AUTOSAR XML (schema 4-3-0)
package /HelloWorld_Generic/Services/Det
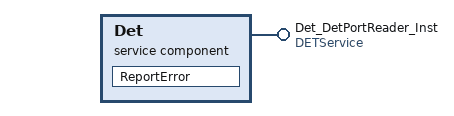
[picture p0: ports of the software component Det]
  service sw component type Det
    provide port Det_DetPortReader_Inst: provided-interface=DETService
    behavior DetBehavior: handle-termination-and-restart=NO-SUPPORT, port-api-option{port-arg-values=[{value=uint16:4097, value-type=uint16}, {value=uint8:0, value-type=uint8}], port=Det_DetPortReader_Inst}
      operation invoked event ReportError_Det_DetPortReader_Inst_ReportError: start-on-event=ReportError, operation=Det_DetPortReader_Inst.ReportError
      runnable ReportError: symbol=Det_ReportError
  swc implementation DetImpl: programming-language=C, vendor-id=60, behavior=DetBehavior
    code-descriptors:
      code src: artifact-descriptors=autosar-engineering-object={short-label=artifactDescriptor, category=artifactDescriptorCategory}
    resource consumption resourceConsumption
package /HelloWorld_Generic/Services/EcuM
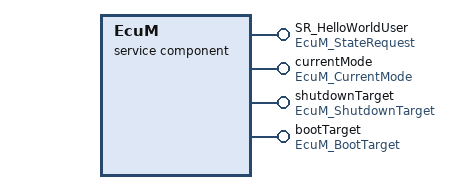
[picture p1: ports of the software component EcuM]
  service sw component type EcuM
    4 x provide port:
      SR_HelloWorldUser: provided-interface=EcuM_StateRequest
      currentMode: provided-interface=EcuM_CurrentMode
      shutdownTarget: provided-interface=EcuM_ShutdownTarget
      bootTarget: provided-interface=EcuM_BootTarget
    behavior EcuMFixedBehavior: data-type-mapping=EcuMFixedTypeMappings, handle-termination-and-restart=NO-SUPPORT, port-api-option{port-defined-argument-value{value=EcuM_UserType:0, value-type=EcuM_UserType}, port=SR_HelloWorldUser}
      9 x operation invoked event:
        RequestRUN_SR_HelloWorldUser_RequestRUN: start-on-event=RequestRUN, operation=SR_HelloWorldUser.RequestRUN
        ReleaseRUN_SR_HelloWorldUser_ReleaseRUN: start-on-event=ReleaseRUN, operation=SR_HelloWorldUser.ReleaseRUN
        RequestPOSTRUN_SR_HelloWorldUser_RequestPOSTRUN: start-on-event=RequestPOSTRUN, operation=SR_HelloWorldUser.RequestPOSTRUN
        ReleasePOSTRUN_SR_HelloWorldUser_ReleasePOSTRUN: start-on-event=ReleasePOSTRUN, operation=SR_HelloWorldUser.ReleasePOSTRUN
        SelectShutdownTarget_shutdownTarget_SelectShutdownTarget: start-on-event=SelectShutdownTarget, operation=shutdownTarget.SelectShutdownTarget
        GetShutdownTarget_shutdownTarget_GetShutdownTarget: start-on-event=GetShutdownTarget, operation=shutdownTarget.GetShutdownTarget
        GetLastShutdownTarget_shutdownTarget_GetLastShutdownTarget: start-on-event=GetLastShutdownTarget, operation=shutdownTarget.GetLastShutdownTarget
        SelectBootTarget_bootTarget_SelectBootTarget: start-on-event=SelectBootTarget, operation=bootTarget.SelectBootTarget
        GetBootTarget_bootTarget_GetBootTarget: start-on-event=GetBootTarget, operation=bootTarget.GetBootTarget
      10 x runnable:
        EcuM_MainFunction
          mode switch point modeSwitchPoint_EcuM_MainFunction_currentMode_currentMode: mode-group=currentMode.currentMode
        RequestRUN: can-be-invoked-concurrently=true, symbol=EcuM_RequestRUN
        ReleaseRUN: can-be-invoked-concurrently=true, symbol=EcuM_ReleaseRUN
        RequestPOSTRUN: can-be-invoked-concurrently=true, symbol=EcuM_RequestPOST_RUN
        ReleasePOSTRUN: can-be-invoked-concurrently=true, symbol=EcuM_ReleasePOST_RUN
        SelectShutdownTarget: can-be-invoked-concurrently=true, symbol=EcuM_SelectShutdownTarget
        GetShutdownTarget: can-be-invoked-concurrently=true, symbol=EcuM_GetShutdownTarget
        GetLastShutdownTarget: can-be-invoked-concurrently=true, symbol=EcuM_GetLastShutdownTarget
        SelectBootTarget: can-be-invoked-concurrently=true, symbol=EcuM_SelectBootTarget
        GetBootTarget: can-be-invoked-concurrently=true, symbol=EcuM_GetBootTarget
  swc implementation EcuMFixedImpl: programming-language=C, vendor-id=60, behavior=EcuMFixedBehavior
    code-descriptors:
      code src: artifact-descriptors=autosar-engineering-object={short-label=artifactDescriptor, category=artifactDescriptorCategory}
    resource consumption resourceConsumption
package /HelloWorld_Generic/Services/NvM
  4 x client server interface, all with is-service=true:
    NvMNotifyInitBlock
      operation InitBlock: possible-error=[NvMNotifyInitBlock/E_OK, NvMNotifyInitBlock/E_NOT_OK]
      error E_OK: error-code=0
      error E_NOT_OK: error-code=1
    NvMNotifyJobFinished
      operation JobFinished: possible-error=NvMNotifyJobFinished/E_OK
        arg ServiceId: type=uint8, direction=IN
        arg JobResult: type=NvM_RequestResultType, direction=IN
      error E_OK: error-code=0
    NvMService
      9 x operation, all with possible-error=[NvMService/E_OK, NvMService/E_NOT_OK]:
        GetErrorStatus
          arg RequestResultPtr: type=NvM_RequestResultType, direction=OUT
        SetDataIndex
          arg DataIndex: type=uint8, direction=IN
        GetDataIndex
          arg DataIndexPtr: type=uint8, direction=OUT
        SetRamBlockStatus
          arg BlockChanged: type=boolean, direction=IN
        ReadBlock
          arg DstPtr: type=VoidPtr, direction=IN
        WriteBlock
          arg SrcPtr: type=ConstVoidPtr, direction=IN
        RestoreBlockDefaults
          arg DstPtr: type=VoidPtr, direction=IN
        EraseNvBlock
        InvalidateNvBlock
      error E_OK: error-code=0
      error E_NOT_OK: error-code=1
    NvMAdmin
      operation SetBlockProtection: possible-error=[NvMAdmin/E_OK, NvMAdmin/E_NOT_OK]
        arg ProtectionEnabled: type=boolean, direction=IN
      error E_OK: error-code=0
      error E_NOT_OK: error-code=1
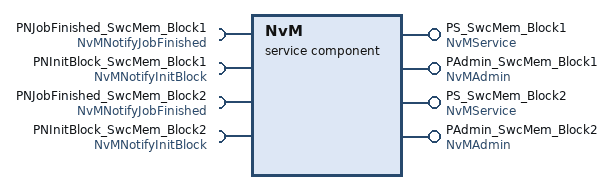
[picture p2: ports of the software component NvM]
  service sw component type NvM
    provide port PS_SwcMem_Block1: provided-interface=NvMService
    require port PNJobFinished_SwcMem_Block1: required-interface=NvMNotifyJobFinished
    require port PNInitBlock_SwcMem_Block1: required-interface=NvMNotifyInitBlock
    provide port PAdmin_SwcMem_Block1: provided-interface=NvMAdmin
    provide port PS_SwcMem_Block2: provided-interface=NvMService
    require port PNJobFinished_SwcMem_Block2: required-interface=NvMNotifyJobFinished
    require port PNInitBlock_SwcMem_Block2: required-interface=NvMNotifyInitBlock
    provide port PAdmin_SwcMem_Block2: provided-interface=NvMAdmin
    behavior NvMBehavior: handle-termination-and-restart=NO-SUPPORT
      20 x operation invoked event:
        GetErrorStatus_PS_SwcMem_Block1_GetErrorStatus: start-on-event=GetErrorStatus, operation=PS_SwcMem_Block1.GetErrorStatus
        GetErrorStatus_PS_SwcMem_Block2_GetErrorStatus: start-on-event=GetErrorStatus, operation=PS_SwcMem_Block2.GetErrorStatus
        SetDataIndex_PS_SwcMem_Block1_SetDataIndex: start-on-event=SetDataIndex, operation=PS_SwcMem_Block1.SetDataIndex
        SetDataIndex_PS_SwcMem_Block2_SetDataIndex: start-on-event=SetDataIndex, operation=PS_SwcMem_Block2.SetDataIndex
        GetDataIndex_PS_SwcMem_Block1_GetDataIndex: start-on-event=GetDataIndex, operation=PS_SwcMem_Block1.GetDataIndex
        GetDataIndex_PS_SwcMem_Block2_GetDataIndex: start-on-event=GetDataIndex, operation=PS_SwcMem_Block2.GetDataIndex
        SetRamBlockStatus_PS_SwcMem_Block1_SetRamBlockStatus: start-on-event=SetRamBlockStatus, operation=PS_SwcMem_Block1.SetRamBlockStatus
        SetRamBlockStatus_PS_SwcMem_Block2_SetRamBlockStatus: start-on-event=SetRamBlockStatus, operation=PS_SwcMem_Block2.SetRamBlockStatus
        ReadBlock_PS_SwcMem_Block1_ReadBlock: start-on-event=ReadBlock, operation=PS_SwcMem_Block1.ReadBlock
        ReadBlock_PS_SwcMem_Block2_ReadBlock: start-on-event=ReadBlock, operation=PS_SwcMem_Block2.ReadBlock
        WriteBlock_PS_SwcMem_Block1_WriteBlock: start-on-event=WriteBlock, operation=PS_SwcMem_Block1.WriteBlock
        WriteBlock_PS_SwcMem_Block2_WriteBlock: start-on-event=WriteBlock, operation=PS_SwcMem_Block2.WriteBlock
        RestoreBlockDefaults_PS_SwcMem_Block1_RestoreBlockDefaults: start-on-event=RestoreBlockDefaults, operation=PS_SwcMem_Block1.RestoreBlockDefaults
        RestoreBlockDefaults_PS_SwcMem_Block2_RestoreBlockDefaults: start-on-event=RestoreBlockDefaults, operation=PS_SwcMem_Block2.RestoreBlockDefaults
        EraseNvBlock_PS_SwcMem_Block1_EraseNvBlock: start-on-event=EraseNvBlock, operation=PS_SwcMem_Block1.EraseNvBlock
        EraseNvBlock_PS_SwcMem_Block2_EraseNvBlock: start-on-event=EraseNvBlock, operation=PS_SwcMem_Block2.EraseNvBlock
        InvalidateNvBlock_PS_SwcMem_Block1_InvalidateNvBlock: start-on-event=InvalidateNvBlock, operation=PS_SwcMem_Block1.InvalidateNvBlock
        InvalidateNvBlock_PS_SwcMem_Block2_InvalidateNvBlock: start-on-event=InvalidateNvBlock, operation=PS_SwcMem_Block2.InvalidateNvBlock
        SetBlockProtection_PAdmin_SwcMem_Block1_SetBlockProtection: start-on-event=SetBlockProtection, operation=PAdmin_SwcMem_Block1.SetBlockProtection
        SetBlockProtection_PAdmin_SwcMem_Block2_SetBlockProtection: start-on-event=SetBlockProtection, operation=PAdmin_SwcMem_Block2.SetBlockProtection
      port-api-options:
        {port-defined-argument-value{value=NvM_BlockIdType:2, value-type=NvM_BlockIdType}, port=PS_SwcMem_Block1}
        {port-defined-argument-value{value=NvM_BlockIdType:2, value-type=NvM_BlockIdType}, port=PAdmin_SwcMem_Block1}
        {port-defined-argument-value{value=NvM_BlockIdType:3, value-type=NvM_BlockIdType}, port=PS_SwcMem_Block2}
        {port-defined-argument-value{value=NvM_BlockIdType:3, value-type=NvM_BlockIdType}, port=PAdmin_SwcMem_Block2}
      11 x runnable:
        NvM_MainFunction
          4 x sync call, all with timeout=0.0:
            PNInitBlock_SwcMem_Block1_InitBlock: operation=PNInitBlock_SwcMem_Block1.InitBlock
            PNJobFinished_SwcMem_Block1_JobFinished: operation=PNJobFinished_SwcMem_Block1.JobFinished
            PNInitBlock_SwcMem_Block2_InitBlock: operation=PNInitBlock_SwcMem_Block2.InitBlock
            PNJobFinished_SwcMem_Block2_JobFinished: operation=PNJobFinished_SwcMem_Block2.JobFinished
        GetErrorStatus: can-be-invoked-concurrently=true, symbol=NvM_GetErrorStatus
        SetDataIndex: can-be-invoked-concurrently=true, symbol=NvM_SetDataIndex
        GetDataIndex: can-be-invoked-concurrently=true, symbol=NvM_GetDataIndex
        SetRamBlockStatus: can-be-invoked-concurrently=true, symbol=NvM_SetRamBlockStatus
        ReadBlock: can-be-invoked-concurrently=true, symbol=NvM_ReadBlock
        WriteBlock: can-be-invoked-concurrently=true, symbol=NvM_WriteBlock
        RestoreBlockDefaults: can-be-invoked-concurrently=true, symbol=NvM_RestoreBlockDefaults
        EraseNvBlock: can-be-invoked-concurrently=true, symbol=NvM_EraseNvBlock
        InvalidateNvBlock: can-be-invoked-concurrently=true, symbol=NvM_InvalidateNvBlock
        SetBlockProtection: can-be-invoked-concurrently=true, symbol=NvM_SetBlockProtection
  swc implementation NvMImpl: programming-language=C, vendor-id=60, behavior=NvMBehavior
    code-descriptors:
      code src: artifact-descriptors=autosar-engineering-object={short-label=artifactDescriptor, category=artifactDescriptorCategory}
    resource consumption resourceConsumption
package /HelloWorld_Generic/Services/Dlt
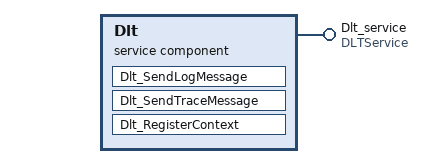
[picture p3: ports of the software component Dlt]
  service sw component type Dlt
    provide port Dlt_service: provided-interface=DLTService
    behavior DltBehavior: handle-termination-and-restart=NO-SUPPORT, port-api-option{port-defined-argument-value{value=Dlt_SessionIDType:4096, value-type=Dlt_SessionIDType}, port=Dlt_service}
      operation invoked event Dlt_SendLogMessage_Dlt_service_SendLogMessage: start-on-event=Dlt_SendLogMessage, operation=Dlt_service.SendLogMessage
      operation invoked event Dlt_SendTraceMessage_Dlt_service_SendTraceMessage: start-on-event=Dlt_SendTraceMessage, operation=Dlt_service.SendTraceMessage
      operation invoked event Dlt_RegisterContext_Dlt_service_RegisterContext: start-on-event=Dlt_RegisterContext, operation=Dlt_service.RegisterContext
      runnable Dlt_SendLogMessage
      runnable Dlt_SendTraceMessage
      runnable Dlt_RegisterContext
  swc implementation DltImpl: programming-language=C, vendor-id=60, behavior=DltBehavior
    code-descriptors:
      code src: artifact-descriptors=autosar-engineering-object={short-label=artifactDescriptor, category=artifactDescriptorCategory}
    resource consumption resourceConsumption
package /HelloWorld_Generic/Services/WdgM
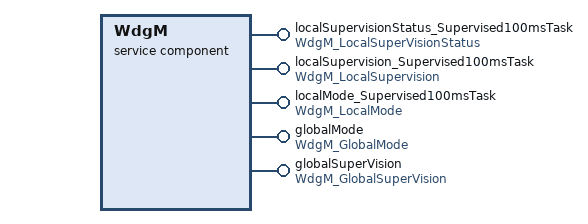
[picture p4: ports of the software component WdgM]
  service sw component type WdgM
    5 x provide port:
      localSupervisionStatus_Supervised100msTask: provided-interface=WdgM_LocalSuperVisionStatus
      localSupervision_Supervised100msTask: provided-interface=WdgM_LocalSupervision
      localMode_Supervised100msTask: provided-interface=WdgM_LocalMode
      globalMode: provided-interface=WdgM_GlobalMode
      globalSuperVision: provided-interface=WdgM_GlobalSuperVision
    behavior WdgMBehavior: data-type-mapping=WdgMTypeMappings, handle-termination-and-restart=NO-SUPPORT
      7 x operation invoked event:
        CheckpointReached_localSupervision_Supervised100msTask_CheckpointReached: start-on-event=CheckpointReached, operation=localSupervision_Supervised100msTask.CheckpointReached
        GetLocalStatus_localSupervisionStatus_Supervised100msTask_GetLocalStatus: start-on-event=GetLocalStatus, operation=localSupervisionStatus_Supervised100msTask.GetLocalStatus
        GetFirstExpiredSEID_globalSuperVision_GetFirstExpiredSEID: start-on-event=GetFirstExpiredSEID, operation=globalSuperVision.GetFirstExpiredSEID
        GetGlobalStatus_globalSuperVision_GetGlobalStatus: start-on-event=GetGlobalStatus, operation=globalSuperVision.GetGlobalStatus
        GetMode_globalSuperVision_GetMode: start-on-event=GetMode, operation=globalSuperVision.GetMode
        PerformReset_globalSuperVision_PerformReset: start-on-event=PerformReset, operation=globalSuperVision.PerformReset
        SetMode_globalSuperVision_SetMode: start-on-event=SetMode, operation=globalSuperVision.SetMode
      port-api-options:
        {port-defined-argument-value{value=WdgM_SupervisedEntityIdType:0, value-type=WdgM_SupervisedEntityIdType}, port=localSupervision_Supervised100msTask}
        {port-defined-argument-value{value=WdgM_SupervisedEntityIdType:0, value-type=WdgM_SupervisedEntityIdType}, port=localSupervisionStatus_Supervised100msTask}
        {indirect-api=true, port-defined-argument-value{value=WdgM_SupervisedEntityIdType:0, value-type=WdgM_SupervisedEntityIdType}, port=localMode_Supervised100msTask}
      8 x runnable:
        WdgM_MainFunction
          mode switch point modeSwitchPoint_WdgM_MainFunction_localMode_Supervised100msTask_currentMode: mode-group=localMode_Supervised100msTask.currentMode
          mode switch point modeSwitchPoint_WdgM_MainFunction_globalMode_currentMode: mode-group=globalMode.currentMode
        CheckpointReached: can-be-invoked-concurrently=true, symbol=WdgM_CheckpointReached
        GetLocalStatus: can-be-invoked-concurrently=true, symbol=WdgM_GetLocalStatus
        GetFirstExpiredSEID: can-be-invoked-concurrently=true, symbol=WdgM_GetFirstExpiredSEID
        GetGlobalStatus: can-be-invoked-concurrently=true, symbol=WdgM_GetGlobalStatus
        GetMode: can-be-invoked-concurrently=true, symbol=WdgM_GetMode
        PerformReset: can-be-invoked-concurrently=true, symbol=WdgM_PerformReset
        SetMode: can-be-invoked-concurrently=true, symbol=WdgM_SetMode
  swc implementation WdgMImpl: programming-language=C, vendor-id=60, behavior=WdgMBehavior
    code-descriptors:
      code src: artifact-descriptors=autosar-engineering-object={short-label=artifactDescriptor, category=artifactDescriptorCategory}
    resource consumption resourceConsumption
package /HelloWorld_Generic/Services/BswM
  impl type ComMModeEnum: compu {0=COMM_NO_COMMUNICATION, 1=COMM_SILENT_COMMUNICATION, 2=COMM_FULL_COMMUNICATION}, implementation-data-type=uint8
  impl type WdgMModeEnum: compu {0=SUPERVISION_DEACTIVATED, 1=SUPERVISION_FAILED, 2=SUPERVISION_EXPIRED, 3=SUPERVISION_STOPPED, 4=SUPERVISION_OK}, implementation-data-type=uint8
  sender receiver interface ComMModeRequestInterface
    data requestedMode: type=ComMModeEnum
  sender receiver interface WdgMModeRequestInterface
    data requestedMode: type=WdgMModeEnum
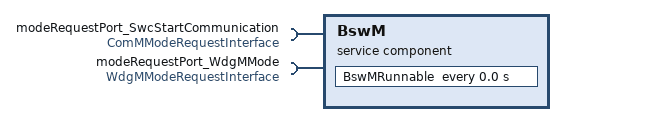
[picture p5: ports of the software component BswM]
  service sw component type BswM
    require port modeRequestPort_SwcStartCommunication: required-interface=ComMModeRequestInterface
    require port modeRequestPort_WdgMMode: required-interface=WdgMModeRequestInterface
    behavior BswMInternalBehavior: handle-termination-and-restart=NO-SUPPORT
      timing event BswMRunnableEvent: start-on-event=BswMRunnable, period=0.0
      runnable BswMRunnable: symbol=BswM_MainFunction
        data-receive-point-by-arguments:
          access dataReceivePoint_BswMRunnable_modeRequestPort_SwcStartCommunication_requestedMode: accessed-variable=modeRequestPort_SwcStartCommunication.requestedMode
          access dataReceivePoint_BswMRunnable_modeRequestPort_WdgMMode_requestedMode: accessed-variable=modeRequestPort_WdgMMode.requestedMode
  swc implementation BswMComponentImpl: programming-language=C, vendor-id=60, behavior=BswMInternalBehavior
    code-descriptors:
      code src: artifact-descriptors=autosar-engineering-object={short-label=artifactDescriptor, category=artifactDescriptorCategory}
    resource consumption resourceConsumption
package /HelloWorld_Generic/Services/Os
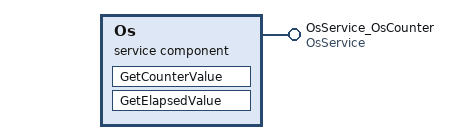
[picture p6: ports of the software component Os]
  service sw component type Os
    provide port OsService_OsCounter: provided-interface=OsService
    behavior OsBehavior: handle-termination-and-restart=NO-SUPPORT, port-api-option{port-defined-argument-value{value=CounterType:0, value-type=CounterType}, port=OsService_OsCounter}
      operation invoked event GetCounterValue_OsService_OsCounter_GetCounterValue: start-on-event=GetCounterValue, operation=OsService_OsCounter.GetCounterValue
      operation invoked event GetElapsedValue_OsService_OsCounter_GetElapsedValue: start-on-event=GetElapsedValue, operation=OsService_OsCounter.GetElapsedValue
      runnable GetCounterValue: symbol=Os_GetCounterValue
      runnable GetElapsedValue: symbol=Os_GetElapsedValue
  swc implementation OsImpl: programming-language=C, vendor-id=60, behavior=OsBehavior
    code-descriptors:
      code src: artifact-descriptors=autosar-engineering-object={short-label=artifactDescriptor, category=artifactDescriptorCategory}
    resource consumption resourceConsumption
package /HelloWorld_Generic/Services/FiM
  impl type FiM_FunctionIdType: implementation-data-type=uint16
  client server interface FunctionInhibition: is-service=true
    operation GetFunctionPermission: possible-error=[FunctionInhibition/E_OK, FunctionInhibition/E_NOT_OK]
      arg Permission: type=boolean, direction=OUT
    error E_OK: error-code=0
    error E_NOT_OK: error-code=1
  client server interface ControlFunctionAvailable: is-service=true
    operation SetFunctionAvailable: possible-error=[ControlFunctionAvailable/E_OK, ControlFunctionAvailable/E_NOT_OK]
      arg Availability: type=boolean, direction=IN
    error E_OK: error-code=0
    error E_NOT_OK: error-code=1
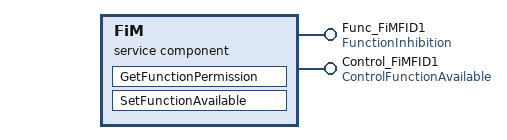
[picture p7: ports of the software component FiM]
  service sw component type FiM
    provide port Func_FiMFID1: provided-interface=FunctionInhibition
    provide port Control_FiMFID1: provided-interface=ControlFunctionAvailable
    behavior FiMBehavior: handle-termination-and-restart=NO-SUPPORT
      operation invoked event GetFunctionPermission_Func_FiMFID1_GetFunctionPermission: start-on-event=GetFunctionPermission, operation=Func_FiMFID1.GetFunctionPermission
      operation invoked event SetFunctionAvailable_Control_FiMFID1_SetFunctionAvailable: start-on-event=SetFunctionAvailable, operation=Control_FiMFID1.SetFunctionAvailable
      port-api-options:
        {port-defined-argument-value{value=FiM_FunctionIdType:0, value-type=FiM_FunctionIdType}, port=Func_FiMFID1}
        {port-defined-argument-value{value=FiM_FunctionIdType:0, value-type=FiM_FunctionIdType}, port=Control_FiMFID1}
      runnable GetFunctionPermission: can-be-invoked-concurrently=true, symbol=FiM_GetFunctionPermission
      runnable SetFunctionAvailable: can-be-invoked-concurrently=true, symbol=FiM_SetFunctionAvailable
  swc implementation FiMImpl: programming-language=C, vendor-id=60, behavior=FiMBehavior
    code-descriptors:
      code src: artifact-descriptors=autosar-engineering-object={short-label=artifactDescriptor, category=artifactDescriptorCategory}
    resource consumption resourceConsumption
package /HelloWorld_Generic/Services/ComM
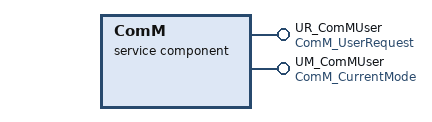
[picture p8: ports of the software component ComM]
  service sw component type ComM
    provide port UR_ComMUser: provided-interface=ComM_UserRequest
    provide port UM_ComMUser: provided-interface=ComM_CurrentMode
    behavior ComMBehavior: data-type-mapping=ComMTypeMappings, handle-termination-and-restart=NO-SUPPORT, port-api-option{port-defined-argument-value{value=ComM_UserHandleType:0, value-type=ComM_UserHandleType}, port=UR_ComMUser}
      4 x operation invoked event:
        RequestComMode_UR_ComMUser_RequestComMode: start-on-event=RequestComMode, operation=UR_ComMUser.RequestComMode
        GetMaxComMode_UR_ComMUser_GetMaxComMode: start-on-event=GetMaxComMode, operation=UR_ComMUser.GetMaxComMode
        GetRequestedComMode_UR_ComMUser_GetRequestedComMode: start-on-event=GetRequestedComMode, operation=UR_ComMUser.GetRequestedComMode
        GetCurrentComMode_UR_ComMUser_GetCurrentComMode: start-on-event=GetCurrentComMode, operation=UR_ComMUser.GetCurrentComMode
      5 x runnable:
        ComM_MainFunction
          mode switch point modeSwitchPoint_ComM_MainFunction_UM_ComMUser_currentMode: mode-group=UM_ComMUser.currentMode
        RequestComMode: can-be-invoked-concurrently=true, symbol=ComM_RequestComMode
        GetMaxComMode: can-be-invoked-concurrently=true, symbol=ComM_GetMaxComMode
        GetRequestedComMode: can-be-invoked-concurrently=true, symbol=ComM_GetRequestedComMode
        GetCurrentComMode: can-be-invoked-concurrently=true, symbol=ComM_GetCurrentComMode
  swc implementation ComMImpl: programming-language=C, vendor-id=60, behavior=ComMBehavior
    code-descriptors:
      code src: artifact-descriptors=autosar-engineering-object={short-label=artifactDescriptor, category=artifactDescriptorCategory}
    resource consumption resourceConsumption
package /HelloWorld_Generic/Services/IoHwAb
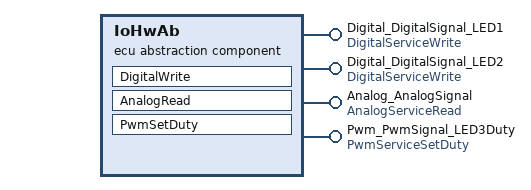
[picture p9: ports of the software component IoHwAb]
  ecu abstraction sw component type IoHwAb
    4 x provide port:
      Digital_DigitalSignal_LED1: provided-interface=DigitalServiceWrite
      Digital_DigitalSignal_LED2: provided-interface=DigitalServiceWrite
      Analog_AnalogSignal: provided-interface=AnalogServiceRead
      Pwm_PwmSignal_LED3Duty: provided-interface=PwmServiceSetDuty
    behavior IoHwAbBehavior: handle-termination-and-restart=NO-SUPPORT
      4 x operation invoked event:
        DigitalWrite_Digital_DigitalSignal_LED1_Write: start-on-event=DigitalWrite, operation=Digital_DigitalSignal_LED1.Write
        DigitalWrite_Digital_DigitalSignal_LED2_Write: start-on-event=DigitalWrite, operation=Digital_DigitalSignal_LED2.Write
        AnalogRead_Analog_AnalogSignal_Read: start-on-event=AnalogRead, operation=Analog_AnalogSignal.Read
        PwmSetDuty_Pwm_PwmSignal_LED3Duty_Set: start-on-event=PwmSetDuty, operation=Pwm_PwmSignal_LED3Duty.Set
      port-api-options:
        {port-defined-argument-value{value=IoHwAb_SignalType_:0, value-type=IoHwAb_SignalType_}, port=Digital_DigitalSignal_LED1}
        {port-defined-argument-value{value=IoHwAb_SignalType_:1, value-type=IoHwAb_SignalType_}, port=Digital_DigitalSignal_LED2}
        {port-defined-argument-value{value=IoHwAb_SignalType_:0, value-type=IoHwAb_SignalType_}, port=Analog_AnalogSignal}
        {port-defined-argument-value{value=IoHwAb_SignalType_:0, value-type=IoHwAb_SignalType_}, port=Pwm_PwmSignal_LED3Duty}
      runnable DigitalWrite: can-be-invoked-concurrently=true, symbol=IoHwAb_Digital_Write
      runnable AnalogRead: can-be-invoked-concurrently=true, symbol=IoHwAb_Analog_Read
      runnable PwmSetDuty: can-be-invoked-concurrently=true, symbol=IoHwAb_Pwm_Set_Duty
  swc implementation IoHwAbImpl: programming-language=C, vendor-id=60, behavior=IoHwAbBehavior
    code-descriptors:
      code src: artifact-descriptors=autosar-engineering-object={short-label=artifactDescriptor, category=artifactDescriptorCategory}
    resource consumption resourceConsumption
package /HelloWorld_Generic/Services/Dem
  impl type Dem_MaxDataValueType: category=ARRAY
    element Dem_MaxDataValueType_elementsImpl: array-size=33, array-size-semantics=FIXED-SIZE, implementation-data-type=uint8
  4 x client server interface, all with is-service=true:
    DiagnosticInfo
      7 x operation:
        GetEventStatus: possible-error=[DiagnosticInfo/E_OK, DiagnosticInfo/E_NOT_OK]
          arg EventStatusExtended: type=Dem_EventStatusExtendedType, direction=OUT
        GetEventFailed: possible-error=[DiagnosticInfo/E_OK, DiagnosticInfo/E_NOT_OK]
          arg EventFailed: type=boolean, direction=OUT
        GetEventTested: possible-error=[DiagnosticInfo/E_OK, DiagnosticInfo/E_NOT_OK]
          arg EventTested: type=boolean, direction=OUT
        GetDTCOfEvent: possible-error=[DiagnosticInfo/E_OK, DiagnosticInfo/E_NOT_OK, DiagnosticInfo/E_NO_DTC_AVAILABLE]
          arg DTCFormat: type=Dem_DTCFormatType, direction=IN
          arg DTCOfEvent: type=uint32, direction=OUT
        GetFaultDetectionCounter: possible-error=[DiagnosticInfo/E_OK, DiagnosticInfo/E_NOT_OK]
          arg FaultDetectionCounter: type=sint8, direction=OUT
        GetEventFreezeFrameData: possible-error=[DiagnosticInfo/E_OK, DiagnosticInfo/E_NOT_OK]
          4 x arg:
            RecordNumber: type=uint8, direction=IN
            ReportTotalRecord: type=boolean, direction=IN
            DataId: type=uint16, direction=IN
            DestBuffer: type=Dem_MaxDataValueType, direction=OUT
        GetEventExtendedDataRecord: possible-error=[DiagnosticInfo/E_OK, DiagnosticInfo/E_NOT_OK]
          arg RecordNumber: type=uint8, direction=IN
          arg DestBuffer: type=Dem_MaxDataValueType, direction=OUT
      error E_OK: error-code=0
      error E_NOT_OK: error-code=1
      error E_NO_DTC_AVAILABLE: error-code=2
    GeneralDiagnosticInfo
      7 x operation:
        GetEventStatus: possible-error=[GeneralDiagnosticInfo/E_OK, GeneralDiagnosticInfo/E_NOT_OK]
          arg EventId: type=Dem_EventIdType, direction=IN
          arg EventStatusExtended: type=Dem_EventStatusExtendedType, direction=OUT
        GetEventFailed: possible-error=[GeneralDiagnosticInfo/E_OK, GeneralDiagnosticInfo/E_NOT_OK]
          arg EventId: type=Dem_EventIdType, direction=IN
          arg EventFailed: type=boolean, direction=OUT
        GetEventTested: possible-error=[GeneralDiagnosticInfo/E_OK, GeneralDiagnosticInfo/E_NOT_OK]
          arg EventId: type=Dem_EventIdType, direction=IN
          arg EventTested: type=boolean, direction=OUT
        GetDTCOfEvent: possible-error=[GeneralDiagnosticInfo/E_OK, GeneralDiagnosticInfo/E_NOT_OK, GeneralDiagnosticInfo/E_NO_DTC_AVAILABLE]
          arg EventId: type=Dem_EventIdType, direction=IN
          arg DTCFormat: type=Dem_DTCFormatType, direction=IN
          arg DTCOfEvent: type=uint32, direction=OUT
        GetFaultDetectionCounter: possible-error=[GeneralDiagnosticInfo/E_OK, GeneralDiagnosticInfo/E_NOT_OK]
          arg EventId: type=Dem_EventIdType, direction=IN
          arg FaultDetectionCounter: type=sint8, direction=OUT
        GetEventFreezeFrameData: possible-error=[GeneralDiagnosticInfo/E_OK, GeneralDiagnosticInfo/E_NOT_OK]
          5 x arg:
            EventId: type=Dem_EventIdType, direction=IN
            RecordNumber: type=uint8, direction=IN
            ReportTotalRecord: type=boolean, direction=IN
            DataId: type=uint16, direction=IN
            DestBuffer: type=Dem_MaxDataValueType, direction=OUT
        GetEventExtendedDataRecord: possible-error=[GeneralDiagnosticInfo/E_OK, GeneralDiagnosticInfo/E_NOT_OK]
          arg EventId: type=Dem_EventIdType, direction=IN
          arg RecordNumber: type=uint8, direction=IN
          arg DestBuffer: type=Dem_MaxDataValueType, direction=OUT
      error E_OK: error-code=0
      error E_NOT_OK: error-code=1
      error E_NO_DTC_AVAILABLE: error-code=2
    OperationCycle
      operation SetOperationCycleState: possible-error=[OperationCycle/E_OK, OperationCycle/E_NOT_OK]
        arg CycleState: type=Dem_OperationCycleStateType, direction=IN
      error E_OK: error-code=0
      error E_NOT_OK: error-code=1
    EventAvailable
      operation SetEventAvailable: possible-error=[EventAvailable/E_OK, EventAvailable/E_NOT_OK]
        arg AvailableStatus: type=boolean, direction=IN
      error E_OK: error-code=0
      error E_NOT_OK: error-code=1
  service sw component type Dem
    5 x provide port:
      Event_TestEvent: provided-interface=DiagnosticMonitor
      EvtInfo_TestEvent: provided-interface=DiagnosticInfo
      GeneralEvtInfo: provided-interface=GeneralDiagnosticInfo
      OpCycle_DemOperationCycle: provided-interface=OperationCycle
      Dcm: provided-interface=DcmIf
    require port CBInitEvt_TestEvent: required-interface=CallbackInitMonitorForEvent
    provide port ControlEventAvailable_TestEvent: provided-interface=EventAvailable
    behavior DemBehavior: handle-termination-and-restart=NO-SUPPORT
      22 x operation invoked event:
        SetEventStatus_Event_TestEvent_SetEventStatus: start-on-event=SetEventStatus, operation=Event_TestEvent.SetEventStatus
        ResetEventStatus_Event_TestEvent_ResetEventStatus: start-on-event=ResetEventStatus, operation=Event_TestEvent.ResetEventStatus
        SetEventDisabled_Event_TestEvent_SetEventDisabled: start-on-event=SetEventDisabled, operation=Event_TestEvent.SetEventDisabled
        PrestoreFreezeFrame_Event_TestEvent_PrestoreFreezeFrame: start-on-event=PrestoreFreezeFrame, operation=Event_TestEvent.PrestoreFreezeFrame
        ClearPrestoredFreezeFrame_Event_TestEvent_ClearPrestoredFreezeFrame: start-on-event=ClearPrestoredFreezeFrame, operation=Event_TestEvent.ClearPrestoredFreezeFrame
        GetEventStatus_EvtInfo_TestEvent_GetEventStatus: start-on-event=GetEventStatus, operation=EvtInfo_TestEvent.GetEventStatus
        GetEventStatus_GeneralEvtInfo_GetEventStatus: start-on-event=GetEventStatus, operation=GeneralEvtInfo.GetEventStatus
        GetEventFailed_EvtInfo_TestEvent_GetEventFailed: start-on-event=GetEventFailed, operation=EvtInfo_TestEvent.GetEventFailed
        GetEventFailed_GeneralEvtInfo_GetEventFailed: start-on-event=GetEventFailed, operation=GeneralEvtInfo.GetEventFailed
        GetEventTested_EvtInfo_TestEvent_GetEventTested: start-on-event=GetEventTested, operation=EvtInfo_TestEvent.GetEventTested
        GetEventTested_GeneralEvtInfo_GetEventTested: start-on-event=GetEventTested, operation=GeneralEvtInfo.GetEventTested
        GetDTCOfEvent_EvtInfo_TestEvent_GetDTCOfEvent: start-on-event=GetDTCOfEvent, operation=EvtInfo_TestEvent.GetDTCOfEvent
        GetDTCOfEvent_GeneralEvtInfo_GetDTCOfEvent: start-on-event=GetDTCOfEvent, operation=GeneralEvtInfo.GetDTCOfEvent
        GetFaultDetectionCounter_EvtInfo_TestEvent_GetFaultDetectionCounter: start-on-event=GetFaultDetectionCounter, operation=EvtInfo_TestEvent.GetFaultDetectionCounter
        GetFaultDetectionCounter_GeneralEvtInfo_GetFaultDetectionCounter: start-on-event=GetFaultDetectionCounter, operation=GeneralEvtInfo.GetFaultDetectionCounter
        GetEventFreezeFrameData_EvtInfo_TestEvent_GetEventFreezeFrameData: start-on-event=GetEventFreezeFrameData, operation=EvtInfo_TestEvent.GetEventFreezeFrameData
        GetEventFreezeFrameData_GeneralEvtInfo_GetEventFreezeFrameData: start-on-event=GetEventFreezeFrameData, operation=GeneralEvtInfo.GetEventFreezeFrameData
        GetEventExtendedDataRecord_EvtInfo_TestEvent_GetEventExtendedDataRecord: start-on-event=GetEventExtendedDataRecord, operation=EvtInfo_TestEvent.GetEventExtendedDataRecord
        GetEventExtendedDataRecord_GeneralEvtInfo_GetEventExtendedDataRecord: start-on-event=GetEventExtendedDataRecord, operation=GeneralEvtInfo.GetEventExtendedDataRecord
        SetOperationCycleState_OpCycle_DemOperationCycle_SetOperationCycleState: start-on-event=SetOperationCycleState, operation=OpCycle_DemOperationCycle.SetOperationCycleState
        ClearDTC_Dcm_ClearDTC: start-on-event=ClearDTC, operation=Dcm.ClearDTC
        SetEventAvailable_ControlEventAvailable_TestEvent_SetEventAvailable: start-on-event=SetEventAvailable, operation=ControlEventAvailable_TestEvent.SetEventAvailable
      port-api-options:
        {port-defined-argument-value{value=Dem_EventIdType:6, value-type=Dem_EventIdType}, port=Event_TestEvent}
        {port-defined-argument-value{value=Dem_EventIdType:6, value-type=Dem_EventIdType}, port=EvtInfo_TestEvent}
        {port-defined-argument-value{value=Dem_EventIdType:6, value-type=Dem_EventIdType}, port=ControlEventAvailable_TestEvent}
        {port-defined-argument-value{value=Dem_OperationCycleIdType:2, value-type=Dem_OperationCycleIdType}, port=OpCycle_DemOperationCycle}
      16 x runnable:
        Dem_MainFunction
        SetEventStatus: can-be-invoked-concurrently=true, symbol=Dem_SetEventStatus
        ResetEventStatus: can-be-invoked-concurrently=true, symbol=Dem_ResetEventStatus
        SetEventDisabled: can-be-invoked-concurrently=true, symbol=Dem_SetEventDisabled
        PrestoreFreezeFrame: can-be-invoked-concurrently=true, symbol=Dem_PrestoreFreezeFrame
        ClearPrestoredFreezeFrame: can-be-invoked-concurrently=true, symbol=Dem_ClearPrestoredFreezeFrame
        GetEventStatus: can-be-invoked-concurrently=true, symbol=Dem_GetEventStatus
        GetEventFailed: can-be-invoked-concurrently=true, symbol=Dem_GetEventFailed
        GetEventTested: can-be-invoked-concurrently=true, symbol=Dem_GetEventTested
        GetDTCOfEvent: can-be-invoked-concurrently=true, symbol=Dem_GetDTCOfEvent
        GetFaultDetectionCounter: can-be-invoked-concurrently=true, symbol=Dem_GetFaultDetectionCounter
        GetEventFreezeFrameData: can-be-invoked-concurrently=true, symbol=Dem_GetEventFreezeFrameData
        GetEventExtendedDataRecord: can-be-invoked-concurrently=true, symbol=Dem_GetEventExtendedDataRecord
        SetOperationCycleState: can-be-invoked-concurrently=true, symbol=Dem_SetOperationCycleState
          sync call CBInitEvt_TestEvent_InitMonitorForEvent: operation=CBInitEvt_TestEvent.InitMonitorForEvent, timeout=0.0
        ClearDTC: symbol=Dem_ClearDTC
          sync call CBInitEvt_TestEvent_InitMonitorForEvent: operation=CBInitEvt_TestEvent.InitMonitorForEvent, timeout=0.0
        SetEventAvailable: can-be-invoked-concurrently=true, symbol=Dem_SetEventAvailable
  swc implementation DemImpl: programming-language=C, vendor-id=60, behavior=DemBehavior
    code-descriptors:
      code src: artifact-descriptors=autosar-engineering-object={short-label=artifactDescriptor, category=artifactDescriptorCategory}
    resource consumption resourceConsumption
package /HelloWorld_Generic/Services/Dcm
  impl type SRRead1_Data_DataType: compu {phys=raw}, implementation-data-type=uint16
  5 x impl type:
    SRRead2_Data_DataType: implementation-data-type=uint16
    SRRead3_Data_DataType: implementation-data-type=boolean
    SecurityLevel_0SeedType: category=ARRAY
      element SecurityLevel_0SeedType_elementsImpl: array-size=4, array-size-semantics=FIXED-SIZE, implementation-data-type=uint8
    SecurityLevel_0KeyType: category=ARRAY
      element SecurityLevel_0KeyType_elementsImpl: array-size=4, array-size-semantics=FIXED-SIZE, implementation-data-type=uint8
    DTRStatusType: implementation-data-type=uint8
  4 x mode switch interface, all with is-service=true:
    DcmEcuReset_Interface
      mode group DcmEcuReset: type=DcmEcuReset
    DcmRapidPowerShutDown_Interface
      mode group DcmRapidPowerShutDown: type=DcmModeRapidPowerShutDown
    DcmCommunicationControl_ComMChannel_Interface
      mode group DcmCommunicationControl_ComMChannel: type=DcmCommunicationControl
    DcmControlDTCSetting_Interface
      mode group DcmControlDTCSetting: type=DcmControlDTCSetting
  mode declaration group DcmDiagnosticSessionControl: initial-mode=DcmConf_DcmDspSessionRow_Default_Session
    mode DcmConf_DcmDspSessionRow_Default_Session
  mode switch interface DcmDiagnosticSessionControl_Interface: is-service=true
    mode group DcmDiagnosticSessionControl: type=DcmDiagnosticSessionControl
  data type mapping set ModeGroupTypeMappings
    mode-request-type-maps:
      implementation-data-type=uint8, mode-group=DcmEcuReset
      implementation-data-type=uint8, mode-group=DcmModeRapidPowerShutDown
      implementation-data-type=uint8, mode-group=DcmCommunicationControl
      implementation-data-type=uint8, mode-group=DcmControlDTCSetting
      implementation-data-type=uint8, mode-group=DcmDiagnosticSessionControl
  impl type SRWrite1_Data_DataType: implementation-data-type=uint16
  impl type SRWrite2_Data_DataType: compu {phys=raw}, implementation-data-type=uint16
  5 x sender receiver interface:
    DataServices_SRWrite1_Data
      data Data: type=SRWrite1_Data_DataType
    DataServices_SRWrite2_Data
      data Data: type=SRWrite2_Data_DataType
    DataServices_SRRead1_Data
      data Data: type=SRRead1_Data_DataType
    DataServices_SRRead2_Data
      data Data: type=SRRead2_Data_DataType
    DataServices_SRRead3_Data
      data Data: type=SRRead3_Data_DataType
  client server interface SecurityAccess_SecurityLevel_0: is-service=true
    operation GetSeed: possible-error=[SecurityAccess_SecurityLevel_0/E_OK, SecurityAccess_SecurityLevel_0/E_NOT_OK, E_PENDING]
      arg OpStatus: type=Dcm_OpStatusType, direction=IN
      arg Seed: type=SecurityLevel_0SeedType, direction=OUT
      arg ErrorCode: type=Dcm_NegativeResponseCodeType, direction=OUT
    operation CompareKey: possible-error=[SecurityAccess_SecurityLevel_0/E_OK, SecurityAccess_SecurityLevel_0/E_NOT_OK, E_PENDING, E_COMPARE_KEY_FAILED]
      arg Key: type=SecurityLevel_0KeyType, direction=IN
      arg OpStatus: type=Dcm_OpStatusType, direction=IN
    4 x error:
      E_OK: error-code=0
      E_NOT_OK: error-code=1
      E_PENDING: error-code=10
      E_COMPARE_KEY_FAILED: error-code=11
  client server interface DCMServices: is-service=true
    4 x operation:
      GetActiveProtocol: possible-error=DCMServices/E_OK
        arg ActiveProtocol: type=Dcm_ProtocolType, direction=OUT
      GetSecurityLevel: possible-error=[DCMServices/E_OK, DCMServices/E_NOT_OK]
        arg SecLevel: type=Dcm_SecLevelType, direction=OUT
      GetSesCtrlType: possible-error=[DCMServices/E_OK, DCMServices/E_NOT_OK]
        arg SesCtrlType: type=Dcm_SesCtrlType, direction=OUT
      ResetToDefaultSession: possible-error=[DCMServices/E_OK, DCMServices/E_NOT_OK]
    error E_OK: error-code=0
    error E_NOT_OK: error-code=1
  client server interface DTRServices: is-service=true
    operation GetDTRValue: possible-error=[DTRServices/E_OK, DTRServices/E_NOT_OK]
      5 x arg:
        OpStatus: type=Dcm_OpStatusType, direction=IN
        Testval: type=uint16, direction=OUT
        Minlimit: type=uint16, direction=OUT
        Maxlimit: type=uint16, direction=OUT
        Status: type=DTRStatusType, direction=OUT
    error E_OK: error-code=0
    error E_NOT_OK: error-code=1
  service sw component type Dcm
    provide port DataServices_SRWrite1_Data_Write: provided-interface=DataServices_SRWrite1_Data
    provide port DataServices_SRWrite2_Data_Write: provided-interface=DataServices_SRWrite2_Data
    5 x require port:
      DataServices_SRRead{1..3}_Data: required-interface=DataServices_SRRead{1..3}_Data
      SecurityAccess_SecurityLevel_0: required-interface=SecurityAccess_SecurityLevel_0
      CallbackDCMRequestServices_DcmDslCallbackDCMRequestService: required-interface=CallbackDCMRequestServices
    5 x provide port:
      DcmEcuReset: provided-interface=DcmEcuReset_Interface
      DcmRapidPowerShutDown: provided-interface=DcmRapidPowerShutDown_Interface
      DcmCommunicationControl_ComMChannel: provided-interface=DcmCommunicationControl_ComMChannel_Interface
      DcmControlDTCSetting: provided-interface=DcmControlDTCSetting_Interface
      DcmDiagnosticSessionControl: provided-interface=DcmDiagnosticSessionControl_Interface
    require port DcmIf: required-interface=DcmIf
    provide port DCMServices: provided-interface=DCMServices
    behavior DcmBehavior: data-type-mapping=ModeGroupTypeMappings, handle-termination-and-restart=NO-SUPPORT
      4 x operation invoked event:
        Dcm_GetSecurityLevel_DCMServices_GetSecurityLevel: start-on-event=Dcm_GetSecurityLevel, operation=DCMServices.GetSecurityLevel
        Dcm_GetSesCtrlType_DCMServices_GetSesCtrlType: start-on-event=Dcm_GetSesCtrlType, operation=DCMServices.GetSesCtrlType
        Dcm_GetActiveProtocol_DCMServices_GetActiveProtocol: start-on-event=Dcm_GetActiveProtocol, operation=DCMServices.GetActiveProtocol
        Dcm_ResetToDefaultSession_DCMServices_ResetToDefaultSession: start-on-event=Dcm_ResetToDefaultSession, operation=DCMServices.ResetToDefaultSession
      timing event Dcm_MainFunction_TimingEvent: start-on-event=Dcm_MainFunction, period=0.0
      5 x runnable:
        Dcm_GetSecurityLevel: can-be-invoked-concurrently=true
        Dcm_GetSesCtrlType: can-be-invoked-concurrently=true
        Dcm_GetActiveProtocol: can-be-invoked-concurrently=true
        Dcm_ResetToDefaultSession: can-be-invoked-concurrently=true
        Dcm_MainFunction
          data-receive-point-by-arguments:
            access dataReceivePoint_Dcm_MainFunction_DataServices_SRRead{1..3}_Data_Data: accessed-variable=DataServices_SRRead{1..3}_Data.Data
          data-send-points:
            access dataSendPoint_Dcm_MainFunction_DataServices_SRWrite1_Data_Write_Data: accessed-variable=DataServices_SRWrite1_Data_Write.Data
            access dataSendPoint_Dcm_MainFunction_DataServices_SRWrite2_Data_Write_Data: accessed-variable=DataServices_SRWrite2_Data_Write.Data
          5 x mode switch point:
            modeSwitchPoint_Dcm_MainFunction_DcmEcuReset_DcmEcuReset: mode-group=DcmEcuReset.DcmEcuReset
            modeSwitchPoint_Dcm_MainFunction_DcmRapidPowerShutDown_DcmRapidPowerShutDown: mode-group=DcmRapidPowerShutDown.DcmRapidPowerShutDown
            modeSwitchPoint_Dcm_MainFunction_DcmCommunicationControl_ComMChannel_DcmCommunicationControl_ComMChannel: mode-group=DcmCommunicationControl_ComMChannel.DcmCommunicationControl_ComMChannel
            modeSwitchPoint_Dcm_MainFunction_DcmControlDTCSetting_DcmControlDTCSetting: mode-group=DcmControlDTCSetting.DcmControlDTCSetting
            modeSwitchPoint_Dcm_MainFunction_DcmDiagnosticSessionControl_DcmDiagnosticSessionControl: mode-group=DcmDiagnosticSessionControl.DcmDiagnosticSessionControl
          5 x sync call, all with timeout=0.0:
            SecurityAccess_SecurityLevel_0_GetSeed: operation=SecurityAccess_SecurityLevel_0.GetSeed
            SecurityAccess_SecurityLevel_0_CompareKey: operation=SecurityAccess_SecurityLevel_0.CompareKey
            CallbackDCMRequestServices_DcmDslCallbackDCMRequestService_StartProtocol: operation=CallbackDCMRequestServices_DcmDslCallbackDCMRequestService.StartProtocol
            CallbackDCMRequestServices_DcmDslCallbackDCMRequestService_StopProtocol: operation=CallbackDCMRequestServices_DcmDslCallbackDCMRequestService.StopProtocol
            DcmIf_ClearDTC: operation=DcmIf.ClearDTC
  swc implementation DcmImpl: programming-language=C, vendor-id=60, behavior=DcmBehavior
    code-descriptors:
      code src: artifact-descriptors=autosar-engineering-object={short-label=artifactDescriptor, category=artifactDescriptorCategory}
    resource consumption resourceConsumption
package /HelloWorld
  composition sw component type TopLevelComposition
    provide port Tx01: provided-interface=BasicSRInterface
    provide port TxAdc: provided-interface=BasicSRInterface2
    require port Rx01: required-interface=BasicSRInterface
    require port Rx01: required-interface=BasicSRInterface
    provide port MemTx: provided-interface=MemoryResIf
    require port MemRx: required-interface=MemoryCmdIf
    15 x component:
      SwcReader: type=SwcReaderType
      SwcWriter: type=SwcWriterType
      SwcMem: type=SwcMemType
      ecuM: type=EcuM
      ioHwAb: type=IoHwAb
      comM: type=ComM
      dcm: type=Dcm
      det: type=Det
      dlt: type=Dlt
      dem: type=Dem
      bswm: type=BswM
      wdgm: type=WdgM
      nvm: type=NvM
      os: type=Os
      fim: type=FiM
    connect ioHwAb.Digital_DigitalSignal_LED1 -> SwcReader.Blinker
    connect SwcReader.ResultPort -> SwcWriter.InputPort
    connect ioHwAb.Digital_DigitalSignal_LED2 -> SwcWriter.Blinker
    connect ioHwAb.Analog_AnalogSignal -> SwcReader.AnalogReader
    connect ioHwAb.Pwm_PwmSignal_LED3Duty -> SwcReader.PWMWriter
    connect ecuM.SR_HelloWorldUser -> SwcReader.RunControl
    connect ecuM.currentMode -> SwcReader.Mode
    connect ecuM.currentMode -> SwcWriter.Mode
    connect comM.UM_ComMUser -> SwcWriter.CommMode
    connect ecuM.currentMode -> SwcMem.Mode
    connect SwcWriter.ComMControl -> bswm.modeRequestPort_SwcStartCommunication
    connect det.Det_DetPortReader_Inst -> SwcReader.Det
    connect dlt.Dlt_service -> SwcReader.Dlt
    connect dem.Event_TestEvent -> SwcReader.Dem_TestEvent
    connect wdgm.localSupervision_Supervised100msTask -> SwcReader.WdgM_LocalSup
    connect wdgm.localMode_Supervised100msTask -> SwcReader.WdgM_LocalMode
    connect nvm.PS_SwcMem_Block1 -> SwcMem.ServicePIM1
    connect nvm.PS_SwcMem_Block2 -> SwcMem.ServicePIM2
    connect SwcMem.JobFinishedPIM1 -> nvm.PNJobFinished_SwcMem_Block1
    connect SwcMem.JobFinishedPIM2 -> nvm.PNJobFinished_SwcMem_Block2
    connect SwcReader.WdgM_StateReq -> bswm.modeRequestPort_WdgMMode
    connect os.OsService_OsCounter -> SwcReader.OsCounter
    connect dcm.DataServices_SRWrite1_Data_Write -> dcm.DataServices_SRRead1_Data
    connect dcm.DataServices_SRWrite2_Data_Write -> dcm.DataServices_SRRead2_Data
    connect fim.Func_FiMFID1 -> SwcReader.FiM_FID1_Inhibition
    delegate SwcWriter.SenderPort <-> outer port Tx01
    delegate SwcWriter.CommandPort <-> outer port TopLevelComposition/Rx01
    delegate SwcMem.SwcMemTx <-> outer port MemTx
    delegate SwcMem.SwcMemRx <-> outer port MemRx
    delegate SwcReader.AdcResult <-> outer port TxAdc
    delegate SwcReader.ReceiverPort <-> outer port TopLevelComposition/Rx01
  system HelloWorld: category=ECU_EXTRACT, system-version=1
    system mapping ImplementationMappings
      sw-impl-mappings:
        15 x swc to impl mapping:
          comMMapping: component-implementation=ComMImpl, component=RootSwComposition.comM
          dcmMapping: component-implementation=DcmImpl, component=RootSwComposition.dcm
          demMapping: component-implementation=DemImpl, component=RootSwComposition.dem
          detMapping: component-implementation=DetImpl, component=RootSwComposition.det
          dltMapping: component-implementation=DltImpl, component=RootSwComposition.dlt
          nvmMapping: component-implementation=NvMImpl, component=RootSwComposition.nvm
          osMapping: component-implementation=OsImpl, component=RootSwComposition.os
          bswMMapping: component-implementation=BswMComponentImpl, component=RootSwComposition.bswm
          ecuMMapping: component-implementation=EcuMFixedImpl, component=RootSwComposition.ecuM
          ioHwAbMapping: component-implementation=IoHwAbImpl, component=RootSwComposition.ioHwAb
          SwcReaderMapping: component-implementation=SwcReaderImpl, component=RootSwComposition.SwcReader
          SwcWriterMapping: component-implementation=SwcWriterImpl, component=RootSwComposition.SwcWriter
          SwcMemMapping: component-implementation=SwcMemImpl, component=RootSwComposition.SwcMem
          wdgMMapping: component-implementation=WdgMImpl, component=RootSwComposition.wdgm
          fimMapping: component-implementation=FiMImpl, component=RootSwComposition.fim
    system mapping SignalMappings
      data-mappings:
        data-element=RootSwComposition.Tx01.data1, system-signal=Tx01data1SSig
        data-element=RootSwComposition.TxAdc.data1, system-signal=TxAdcdata1SSig
        data-element=RootSwComposition.Rx01.data1, system-signal=Rx01data1SSig
        data-element=RootSwComposition.Rx01.cmd, system-signal=Rx01CmdSSig
        data-element=RootSwComposition.MemRx.command, system-signal=MemRxCmdSSig
        data-element=RootSwComposition.MemRx.blockId, system-signal=MemRxBlockIdSSig
        data-element=RootSwComposition.MemRx.payload, system-signal=MemRxPayloadSSig
        data-element=RootSwComposition.MemTx.result, system-signal=MemTxResSSig
        data-element=RootSwComposition.MemTx.blockId, system-signal=MemTxBlockIdSSig
        data-element=RootSwComposition.MemTx.payload, system-signal=MemTxPayloadSSig
    root-software-compositions:
      root sw composition prototype RootSwComposition: software-composition=TopLevelComposition
package /HelloWorld/Communication
  pdu Rx01data1IPdu: unused-bit-pattern=0
    signal Rx01data1ISig: 0 bit, system signal Rx01data1SSig, data-type-policy=NETWORK-REPRESENTATION-FROM-COM-SPEC
    signal Rx01CmdIsig: 0 bit, system signal Rx01CmdSSig, data-type-policy=NETWORK-REPRESENTATION-FROM-COM-SPEC
  pdu Tx01data1IPdu: unused-bit-pattern=0
    signal Tx01data1ISig: 0 bit, system signal Tx01data1SSig, data-type-policy=NETWORK-REPRESENTATION-FROM-COM-SPEC
  pdu TxAdcdata1IPdu: unused-bit-pattern=0
    signal TxAdcdata1ISig: 0 bit, system signal TxAdcdata1SSig, data-type-policy=NETWORK-REPRESENTATION-FROM-COM-SPEC
  pdu SwcMemRx: unused-bit-pattern=0
    signal MemRxCmdISig: 0 bit, system signal MemRxCmdSSig, data-type-policy=NETWORK-REPRESENTATION-FROM-COM-SPEC
    signal MemRxPayloadISig: 0 bit, system signal MemRxPayloadSSig, data-type-policy=NETWORK-REPRESENTATION-FROM-COM-SPEC
    signal MemRxBlockIdISig: 0 bit, system signal MemRxBlockIdSSig, data-type-policy=NETWORK-REPRESENTATION-FROM-COM-SPEC
  pdu SwcMemTx: unused-bit-pattern=0
    signal MemTxResISig: 0 bit, system signal MemTxResSSig, data-type-policy=NETWORK-REPRESENTATION-FROM-COM-SPEC
    signal MemTxPayloadISig: 0 bit, system signal MemTxPayloadSSig, data-type-policy=NETWORK-REPRESENTATION-FROM-COM-SPEC
    signal MemTxBlockIdISig: 0 bit, system signal MemTxBlockIdSSig, data-type-policy=NETWORK-REPRESENTATION-FROM-COM-SPEC
package /Interfaces
  impl type NvmCmdType: compu {0=SWCMEM_REQ_IDLE, 1=SWCMEM_REQ_WRITE_BLOCK, 2=SWCMEM_REQ_READ_BLOCK}, implementation-data-type=uint8
  impl type NvmResType: compu {0=SWCMEM_RES_NONE, 1=SWCMEM_RES_WRITE_BLOCK_OK, 2=SWCMEM_RES_WRITE_BLOCK_FAILED, 3=SWCMEM_RES_READ_BLOCK_OK, 4=SWCMEM_RES_READ_BLOCK_FAILED, 5=SWCMEM_RES_REQ_BUSY, 6=SWCMEM_RES_REQ_INVALID}, implementation-data-type=uint8
  impl type TestCmdType: compu {0=TESTER_CMD_NONE, 1=TESTER_CMD_SHUTDOWN, 2=TESTER_CMD_ENABLE_WDG, 3=TESTER_CMD_DISABLE_WDG, 4=TESTER_CMD_STOP_WDG_KICK}, implementation-data-type=uint8
  4 x sender receiver interface:
    BasicSRInterface
      data data1: type=uint32
      data cmd: type=TestCmdType
    BasicSRInterface2
      data data1: type=sint32
    MemoryCmdIf
      data command: type=NvmCmdType
      data blockId: type=uint8
      data payload: type=uint32
    MemoryResIf
      data result: type=NvmResType
      data blockId: type=uint8
      data payload: type=uint32
package /SwcMem
  application sw component type SwcMemType
    require port SwcMemRx: required-interface=MemoryCmdIf
    provide port SwcMemTx: provided-interface=MemoryResIf
    provide port JobFinishedPIM1: provided-interface=NvMNotifyJobFinished
    provide port JobFinishedPIM2: provided-interface=NvMNotifyJobFinished
    require port ServicePIM1: required-interface=NvMService
    require port ServicePIM2: required-interface=NvMService
    require port Mode: required-interface=EcuM_CurrentMode
    behavior SwcMemBehavior: data-type-mapping=EcuMFixedTypeMappings, handle-termination-and-restart=NO-SUPPORT
      swc mode switch event InitEvent: start-on-event=SwcMemBehavior/Init, activation=ON-EXIT, mode=Mode.currentMode.STARTUP
      data received event SwcMemCmdEvent: start-on-event=Main, data=SwcMemRx.command
      operation invoked event JobFinishedPIM1_JobFinishedPIM1_JobFinished: start-on-event=JobFinishedPIM1, operation=JobFinishedPIM1.JobFinished
      operation invoked event JobFinishedPIM2_JobFinishedPIM2_JobFinished: start-on-event=JobFinishedPIM2, operation=JobFinishedPIM2.JobFinished
      per instance memory PIM1: type=PIM1Type, type-definition=uint32
      per instance memory PIM2: type=PIM2Type, type-definition=uint32
      4 x runnable:
        Init: symbol=SwcMem_Init
        Main: symbol=SwcMem_MainFunction
          data-read-access:
            access dataReadAccess_Main_SwcMemRx_command: accessed-variable=SwcMemRx.command
            access dataReadAccess_Main_SwcMemRx_blockId: accessed-variable=SwcMemRx.blockId
            access dataReadAccess_Main_SwcMemRx_payload: accessed-variable=SwcMemRx.payload
          data-send-points:
            access dataSendPoint_Main_SwcMemTx_result: accessed-variable=SwcMemTx.result
            access dataSendPoint_Main_SwcMemTx_blockId: accessed-variable=SwcMemTx.blockId
            access dataSendPoint_Main_SwcMemTx_payload: accessed-variable=SwcMemTx.payload
          sync call ServicePIM1_SetRamBlockStatus: operation=ServicePIM1.SetRamBlockStatus, timeout=0.0
          sync call ServicePIM2_ReadBlock: operation=ServicePIM2.ReadBlock, timeout=0.0
          sync call ServicePIM2_WriteBlock: operation=ServicePIM2.WriteBlock, timeout=0.0
        JobFinishedPIM1: symbol=SwcMem_JobFinishedPIM1
        JobFinishedPIM2: symbol=SwcMem_JobFinishedPIM2
  swc implementation SwcMemImpl: programming-language=C, vendor-id=0, behavior=SwcMemBehavior
    code-descriptors:
      code src: artifact-descriptors=autosar-engineering-object={short-label=artifactDescriptor, category=artifactDescriptorCategory}
    resource consumption resourceConsumption
package /SwcReader
  application sw component type SwcReaderType
    4 x require port:
      OsCounter: required-interface=OsService
      ReceiverPort: required-interface=BasicSRInterface
      Blinker: required-interface=DigitalServiceWrite
      AnalogReader: required-interface=AnalogServiceRead
    provide port ResultPort: provided-interface=BasicSRInterface
    provide port AdcResult: provided-interface=BasicSRInterface2
    8 x require port:
      PWMWriter: required-interface=PwmServiceSetDuty
      Mode: required-interface=EcuM_CurrentMode
      RunControl: required-interface=EcuM_StateRequest
      Det: required-interface=DETService
      Dlt: required-interface=DLTService
      Dem_TestEvent: required-interface=DiagnosticMonitor
      WdgM_LocalSup: required-interface=WdgM_LocalSupervision
      WdgM_LocalMode: required-interface=WdgM_LocalMode
    provide port WdgM_StateReq: provided-interface=WdgMModeRequestInterface
    require port FiM_FID1_Inhibition: required-interface=FunctionInhibition
    behavior SwcReaderBehavior: data-type-mapping=[EcuMFixedTypeMappings, WdgMTypeMappings], handle-termination-and-restart=NO-SUPPORT
      swc mode switch event localModeEvent: start-on-event=SwcReaderRunnable, activation=ON-ENTRY, mode=WdgM_LocalMode.currentMode.SUPERVISION_FAILED
      timing event SwcReaderRunnable_timingEvent_0_1: start-on-event=SwcReaderRunnable, period=0.1
      swc mode switch event InitEvent: start-on-event=SwcReaderBehavior/Init, activation=ON-EXIT, mode=Mode.currentMode.STARTUP
      runnable SwcReaderRunnable: symbol=swcReaderRunnable
        data-read-access:
          access dataReadAccess_SwcReaderRunnable_ReceiverPort_data1: accessed-variable=ReceiverPort.data1
          access dataReadAccess_SwcReaderRunnable_ReceiverPort_cmd: accessed-variable=ReceiverPort.cmd
        data-write-access:
          access dataWriteAccess_SwcReaderRunnable_ResultPort_data1: accessed-variable=ResultPort.data1
          access dataWriteAccess_SwcReaderRunnable_AdcResult_data1: accessed-variable=AdcResult.data1
          access dataWriteAccess_SwcReaderRunnable_WdgM_StateReq_requestedMode: accessed-variable=WdgM_StateReq.requestedMode
        11 x sync call, all with timeout=0.0:
          OsCounter_GetCounterValue: operation=OsCounter.GetCounterValue
          OsCounter_GetElapsedValue: operation=OsCounter.GetElapsedValue
          BlinkerCallPoint: operation=Blinker.Write
          AnalogCallPoint: operation=AnalogReader.Read
          Det_ReportError: operation=Det.ReportError
          PWMCallPoint: operation=PWMWriter.Set
          Dlt_SendLogMessage: operation=Dlt.SendLogMessage
          Dem_TestEvent_SetEventStatus: operation=Dem_TestEvent.SetEventStatus
          WdgM_LocalSup_CheckpointReached: operation=WdgM_LocalSup.CheckpointReached
          RunControl_ReleaseRUN: operation=RunControl.ReleaseRUN
          FiM_FID1_Inhibition_GetFunctionPermission: operation=FiM_FID1_Inhibition.GetFunctionPermission
      runnable Init: symbol=swcReaderInit
        sync call RunControl_RequestRUN: operation=RunControl.RequestRUN, timeout=0.0
  swc implementation SwcReaderImpl: programming-language=C, vendor-id=0, behavior=SwcReaderBehavior
    code-descriptors:
      code src: artifact-descriptors=autosar-engineering-object={short-label=artifactDescriptor, category=artifactDescriptorCategory}
    resource consumption resourceConsumption
package /SwcWriter
  application sw component type SwcWriterType
    require port CommandPort: required-interface=BasicSRInterface
    require port InputPort: required-interface=BasicSRInterface
    provide port SenderPort: provided-interface=BasicSRInterface
    require port Blinker: required-interface=DigitalServiceWrite
    provide port ComMControl: provided-interface=ComMModeRequestInterface
    require port Mode: required-interface=EcuM_CurrentMode
    require port CommMode: required-interface=ComM_CurrentMode
    behavior SwcWriterBehavior: data-type-mapping=[EcuMFixedTypeMappings, ComMTypeMappings], handle-termination-and-restart=NO-SUPPORT
      timing event SwcWriterRunnable_timingEvent_1_0: start-on-event=SwcWriterRunnable, period=1.0
      swc mode switch event InitEvent: start-on-event=SwcWriterBehavior/Init, activation=ON-EXIT, mode=Mode.currentMode.STARTUP
      swc mode switch event FullCommEvent: start-on-event=FullCommunication, activation=ON-ENTRY, mode=CommMode.currentMode.COMM_FULL_COMMUNICATION
      runnable SwcWriterRunnable: symbol=swcWriterRunnable
        data-read-access:
          access dataReadAccess_SwcWriterRunnable_CommandPort_cmd: accessed-variable=CommandPort.cmd
          access dataReadAccess_SwcWriterRunnable_InputPort_data1: accessed-variable=InputPort.data1
        data-write-access:
          access dataWriteAccess_SwcWriterRunnable_SenderPort_data1: accessed-variable=SenderPort.data1
        sync call Blinker2CallPoint: operation=Blinker.Write, timeout=0.0
      runnable Init: symbol=SwcWriterInit
        data-write-access:
          access dataWriteAccess_Init_ComMControl_requestedMode: accessed-variable=ComMControl.requestedMode
      runnable FullCommunication: symbol=SwcWriterCommunication
  swc implementation SwcWriterImpl: programming-language=C, vendor-id=0, behavior=SwcWriterBehavior
    code-descriptors:
      code src: artifact-descriptors=autosar-engineering-object={short-label=artifactDescriptor, category=artifactDescriptorCategory}
    resource consumption resourceConsumption
